# RL6955_IP_SVD register map
Vendor: Realtek
Registers are 32-bit, read-write, reset 0x0 unless marked. A register's access mark holds for its fields unless they carry their own. Offsets are from the block's base; [hi:lo] are bit positions; {n}, {i} and the like mark numbered series; <NAME> marks a mode.

## PLL_REG
Base 0x41000500
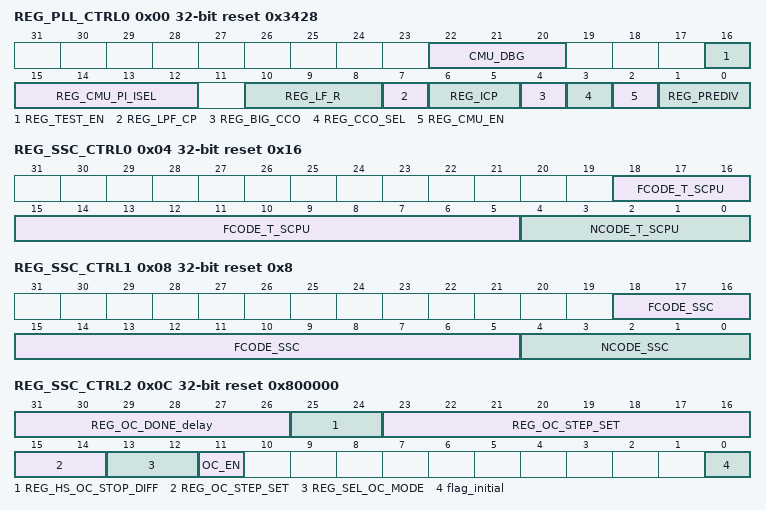
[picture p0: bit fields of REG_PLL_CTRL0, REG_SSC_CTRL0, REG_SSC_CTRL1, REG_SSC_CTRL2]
0x00 REG_PLL_CTRL0 access per field reset 0x3428
  [22:20] CMU_DBG ro
  [16] REG_TEST_EN rw — DEBUG信号
  [15:12] REG_CMU_PI_ISEL rw — 选择PI电流ISEL的大小: 0000:ICP=3.125u 1000:ICP=28.125u 0001:ICP=6.25u 1001:ICP=31.25u 0010:ICP=9.375u 1010:ICP=34.375u 0011:ICP=12.5u 1011:ICP=37.5u 0100:ICP=15.625u 1100:ICP=40.625u 0101:ICP=18.75u 1101:ICP=43.75u 0110:ICP=21.875u 1110:ICP=46.875u 0111:ICP=25u 1111:ICP=50u
  [10:8] REG_LF_R rw — lpf电阻RS选择: 000: 3.1KΩ , 001: 6.1KΩ , 010: 9.2KΩ , 011: 12.2KΩ, 100: 15.2KΩ, 101: 18.2KΩ, 110: 21.3KΩ, 111: 24.3KΩ
  [7] REG_LPF_CP rw — lpf小电容CS选择: 0:CS=1p 1:CS=2p
  [6:5] REG_ICP rw — CP电流ICP选择: 00:ICP=5u 01:ICP=10u 10:ICP=15u 11:ICP=20u
  [4] REG_BIG_CCO rw — 控制KVCO曲线斜率
  [3] REG_CCO_SEL rw — 控制选择CCO mode还是VCO mode 0: vco mode 1: cco mode
  [2] REG_CMU_EN rw — PLL的使能信号
  [1:0] REG_PREDIV rw — 对PLL输入参考频率ckin进行pre_divide: 00:ckin/1 01:ckin/2 10:ckin/4 11:ckin/8
0x04 REG_SSC_CTRL0 reset 0x16
  [18:5] FCODE_T_SCPU — VCO target频率对应的 Fcode
  [4:0] NCODE_T_SCPU — VCO target频率对应的 Ncode
0x08 REG_SSC_CTRL1 reset 0x8
  [18:5] FCODE_SSC — SSC低点频率对应的Fcode SSC时,频率会在"target频率" 与 "SSC低点频率"之间以三角波形式变化. Note: SSC低点 频率要小于target频率
  [4:0] NCODE_SSC — SSC低点频率对应的Ncode SSC时,频率会在"target频率" 与 "SSC低点频率"之间以三角波形式变化. Note: SSC低点 频率要小于target频率
0x0C REG_SSC_CTRL2 reset 0x800000
  [31:26] REG_OC_DONE_delay — OC_EN 1->0后,多久将SSCD送出的flag信号OC_DONE 置1 判断NFcode==target NF code后, delay REG_OC_DONE_delay[5:0]个CKXSTAL周期, OC_DONE 置1
  [25:24] REG_HS_OC_STOP_DIFF — 线性超频mode01时,设定一步超频后离target NFcode的delta值
  [23:14] REG_OC_STEP_SET — 线性超频且超频mode=00时,每次跳变的step
  [13:12] REG_SEL_OC_MODE — 线性超频模式: 00: 以每次跳变REG_OC_STEP_SET[9:0]的方式线性超频到target值. a)如果 "当前NF 值" - "target NF 值" > 与REG_SEL_OC_STEP_SET[9:0], 每次跳变REG_SEL_OC_STEP_SET[9:0] b) 如果 "当前NF 值" - "target NF 值" <= 与REG_SEL_OC_STEP_SET[9:0], 直接超频到target NF 值 01: 先直接一步超频到 "target NF code" - delta, 然后按mode 00 方式继续超频. delta 大小由REG_HS_OC_STOP_DIFF[1:0] 设定 10: 先直接一步讲{Ncode[7:0], Fcode[12:6]}超频到 target值,然后按mode 00 方式继续超频 11: 同mode 10
  [11] OC_EN — OC_EN 0->1 toggle ,才会把NCODE_T_SCPU[7:0], FCODE_T_SCPU[12:0], NCODE_SSC[7:0], FCODE_SSC[12:0],GRAN_EST[20:0] load进来
  [0] flag_initial — 线性超频控制信号 0: 不执行线性超频,OC_EN 0->1 toggle后,直接把NFcode 吃进来 1: 执行线性超频,OC_EN 0->1 toggle后,按设定的线性超频模式逐渐超频到target NF 值
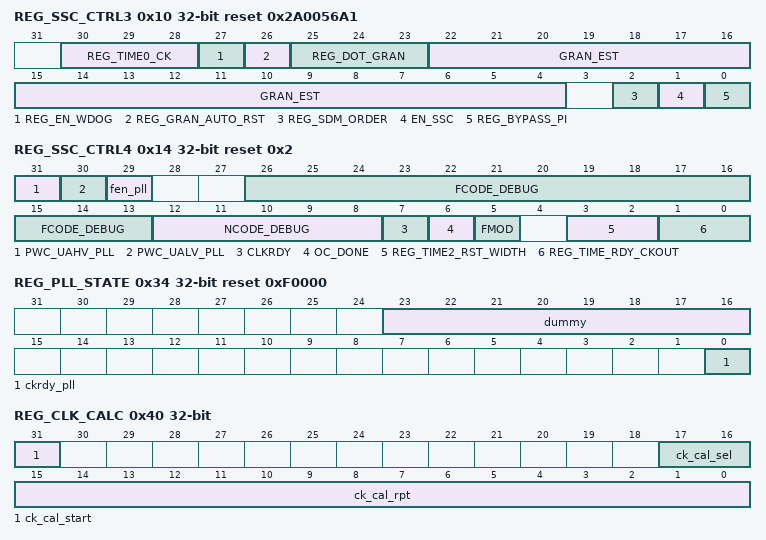
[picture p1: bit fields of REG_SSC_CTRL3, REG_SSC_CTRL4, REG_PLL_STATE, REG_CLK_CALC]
0x10 REG_SSC_CTRL3 reset 0x2A0056A1
  [30:28] REG_TIME0_CK — PLL watchdog timer: 3'b000: watchdog compare CKREF&CKBK frequency Every 2 CKREF period 3'b001: watchdog compare CKREF&CKBK frequency Every 200 CKREF period 3'b010: watchdog compare CKREF&CKBK frequency Every 600 CKREF period 3'b011: watchdog compare CKREF&CKBK frequency Every 1200 CKREF period 3'b100: watchdog compare CKREF&CKBK frequency Every 3000 CKREF period 3'b101: watchdog compare CKREF&CKBK frequency Every 6400 CKREF period 3'b110: watchdog compare CKREF&CKBK frequency Every 12800 CKREF period 3'b111: watchdog compare CKREF&CKBK frequency Every 16000 CKREF period
  [27] REG_EN_WDOG — PLL watchdog enable =0: disable PLL watchdog =1: enable PLL watchdog
  [26] REG_GRAN_AUTO_RST — SSC step auto reset control: =0: not auto reset =1: SSC step在三角波拐点处每次都 reset 到0, 然后再将GRAN_EST, REG_DOT_GRAN赋给SSC step
  [25:23] REG_DOT_GRAN — 控制GRAN_EST[20:0]的小数点位置
  [22:4] GRAN_EST — SSC step (SSC depth&frequence计算公式见ppt)
  [2] REG_SDM_ORDER — Sigma-delta order: =0: 1阶 sigma-delta =1: 2阶 sigma-delta
  [1] EN_SSC — SSC enable: =0: disable SSC =1: enable SSC
  [0] REG_BYPASS_PI — bypass PI =0: 送给PLL Loop PI的phase selsect信号正常toggle =1:送给PLL Loop PI的phase selsect==0
0x14 REG_SSC_CTRL4 access per field reset 0x2
  [31] PWC_UAHV_PLL rw — keep UA33PC_EN for PLL
  [30] PWC_UALV_PLL rw — keep UA10PC_EN for PLL
  [29] fen_pll rw — SSC global reset, at same time reset PLL also when pll on , set it to 1 after PWC is enable when pll off , set it to 0 at last
  [26:13] FCODE_DEBUG ro
  [12:8] NCODE_DEBUG ro
  [7] CLKRDY ro
  [6] OC_DONE ro
  [5] FMOD ro
  [3:2] REG_TIME2_RST_WIDTH rw — PLL watchdog signal pulse width: 2'b00: watchdog reset pulse width =2 CKREF period 2'b01: watchdog reset pulse width =4 CKREF period 2'b01: watchdog reset pulse width =8 CKREF period 2'b01: watchdog reset pulse width =20 CKREF period
  [1:0] REG_TIME_RDY_CKOUT rw — output signal CLKRDY delay control
0x34 REG_PLL_STATE access per field reset 0xF0000
  [23:16] dummy rw
  [0] ckrdy_pll ro — PLL clock is ready
0x38 REG_DEBUG ro
  [31:0] adbg_aux — dummy
0x3C REG_DUMMY
  [7:0] lpad_dummy — dummy
0x40 REG_CLK_CALC access per field
  [31] ck_cal_start rw — Start clk calibration . This bit will auto-set to 0 when cal done .
  [17:16] ck_cal_sel rw — Calibration clock selection . The refrence clock is xtal clock. 0: OSC4M 1: AON100K 2: AON128K for SDM
  [15:0] ck_cal_rpt ro — Clock calibration result
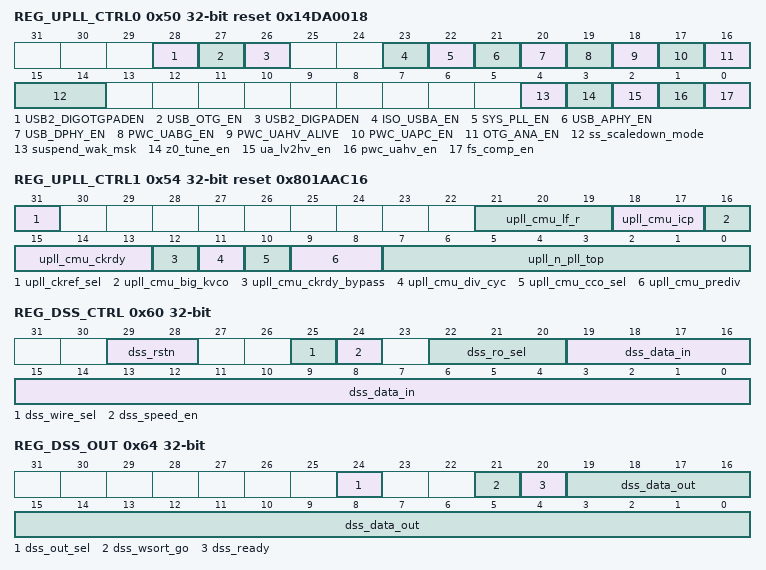
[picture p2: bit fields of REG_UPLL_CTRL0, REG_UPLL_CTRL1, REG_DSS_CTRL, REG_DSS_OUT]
0x50 REG_UPLL_CTRL0 reset 0x14DA0018
  [28] USB2_DIGOTGPADEN — 1: usb otg pad used as digital IO pad
  [27] USB_OTG_EN — 0: disable otg signals to usb mac
  [26] USB2_DIGPADEN — 1: usb pad used as digital IO pad
  [23] ISO_USBA_EN — 1: Enable isolation signal from USBPHY analog 0: disable
  [22] SYS_PLL_EN — uphy pll enable request, keep pll alive when usb entering suspend state both usb_aphy_en and sys_pll_en should be set 0 to disable uphy pll
  [21] USB_APHY_EN — usb aphy power on reset, low active this bit also controls uphy pll: can only write 1 after xtal normal 40M is ready write 0, uphy pll will be disabled Note: when power on , HW pmc only set this bit to 1 , other using default value , and USB pll can power up
  [20] USB_DPHY_EN — usb dphy power on reset, low active
  [19] PWC_UABG_EN — 1: enable USBPHY BG power cut
  [18] PWC_UAHV_ALIVE — keep UA33PC_EN alive for usb suspend
  [17] PWC_UAPC_EN — enable USBPHY power cut UA33PC_EN = PWC_UAHV_ALIVE | PWC_UAPC_EN UA10PC_EN = PWC_UAPC_EN
  [16] OTG_ANA_EN — 1: enable usb aphy lv2hv, hv2lv check for otg
  [15:14] ss_scaledown_mode — use scaled-down timing values for usb, resulting in faster simulations
  [4] suspend_wak_msk — set 0 to mask usb suspendm(keep 1) at normal state after receiving usb suspend interrupt, set this bit to 1 to enable resume(from suspend) wake event
  [3] z0_tune_en — Zo_Tune , 45Ωauto calibration(Port-1 only) 0: Zo_Tune disable 1: Zo_Tune enable
  [2] ua_lv2hv_en — enable usb comparator l2h level shifter
  [1] pwc_uahv_en — enable usb comparator 3.3v power cut
  [0] fs_comp_en — enable usb full-speed differential comparator
0x54 REG_UPLL_CTRL1 reset 0x801AAC16
  [31] upll_ckref_sel — ECO, REG_CKREF_SEL for usbphy, reset default 1
  [21:19] upll_cmu_lf_r — Resistance of loop filter, adjust for PLL bandwidth 000: 3.1KΩ , 001: 6.1KΩ , 010: 9.2KΩ , 011: 12.2KΩ, 100: 15.2KΩ, 101: 18.2KΩ, 110: 21.3KΩ, 111: 24.3KΩ
  [18:17] upll_cmu_icp — Charge-Pump current, adjust for PLL bandwidth 00: 5uA 01: 10uA 10: 15uA 11: 20uA
  [16] upll_cmu_big_kvco — Control Kvco of CCO, adjust for bandwidth & jitter 0: Smaller KVCO 1: Larger KVCO Kvco(Hz/V): the frequency change per 1V of CCO
  [15:13] upll_cmu_ckrdy — PLL480M clock output after ∆T for waiting 480MHz clock ready, ∆T: 000: 21*TPLLCKIN, 001: 22*TPLLCKIN 010: 25*TPLLCKIN, 011: 27*TPLLCKIN 100: 210*TPLLCKIN, 101: 212*TPLLCKIN 110: 216*TPLLCKIN, 111: 3*216*TPLLCKIN TPLLCKIN: period of PLLCKIN
  [12] upll_cmu_ckrdy_bypass — Bypass the time delay of CKRDY 1: Bypass CKRDY 0: PLL480M clock output after ∆T ∆T: delay time, refer to REG_CMU_CKRDY
  [11] upll_cmu_div_cyc — Pulse width of divider output clock, adjust for PI monotonic phase transfer 0: 3/480e6 cycle is logic 1 1: 6/480e6 cycle is logic 1
  [10] upll_cmu_cco_sel — 1: VCO mode 0: CCO mode
  [9:8] upll_cmu_prediv — Division-ratio of pre-divider for PLL clock in 11: fPLLCKIN pre-divided-by-8 10: fPLLCKIN pre-divided-by-4 01: fPLLCKIN pre-divided-by-2 00: fPLLCKIN pre-divided-by-1 fPLLCKIN: frequency of PLLCKIN
  [7:0] upll_n_pll_top — (n+2) divider's divisor
0x60 REG_DSS_CTRL
  [29:28] dss_rstn, [25] dss_wire_sel, [24] dss_speed_en, [22:20] dss_ro_sel, [19:0] dss_data_in
0x64 REG_DSS_OUT access per field
  [24] dss_out_sel rw — 0: select lvt dss 1: select uhvt dss
  [21] dss_wsort_go ro
  [20] dss_ready ro
  [19:0] dss_data_out ro
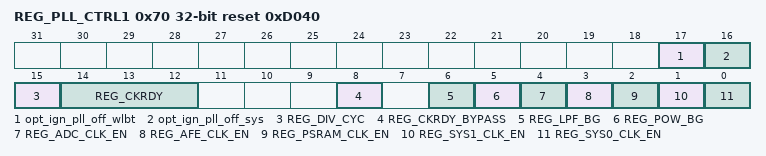
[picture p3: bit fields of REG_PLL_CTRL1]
0x70 REG_PLL_CTRL1 reset 0xD040
  [17] opt_ign_pll_off_wlbt — option for pll ignore wlbt req off , it always on
  [16] opt_ign_pll_off_sys — option for pll ignore sys req off , it always on
  [15] REG_DIV_CYC
  [14:12] REG_CKRDY
  [8] REG_CKRDY_BYPASS
  [6] REG_LPF_BG
  [5] REG_POW_BG
  [4] REG_ADC_CLK_EN
  [3] REG_AFE_CLK_EN
  [2] REG_PSRAM_CLK_EN
  [1] REG_SYS1_CLK_EN
  [0] REG_SYS0_CLK_EN — Note,sys0 gating is in digital domain
